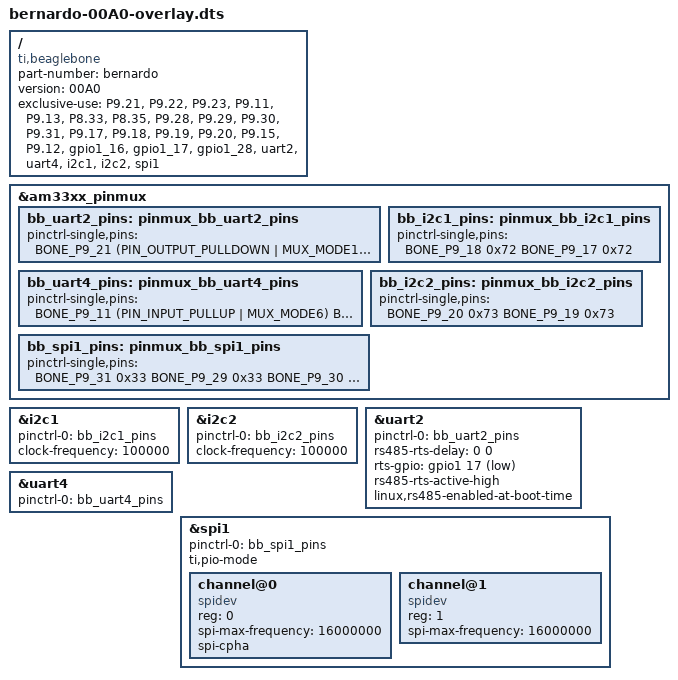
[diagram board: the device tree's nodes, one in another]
/* cape-bernardo.dts
* Written by Bert Outtier <outtierbert@gmail.com>
*
* TODO license
*/
/dts-v1/;
/plugin/;

#include <dt-bindings/board/am335x-bbw-bbb-base.h>
#include <dt-bindings/pinctrl/am33xx.h>

/ {
    compatible = "ti,beaglebone", "ti,beaglebone-black", "ti,beaglebone-green";

    /* identification */
    part-number = "bernardo";
    version = "00A0";

    /* state the resources this cape uses */
    exclusive-use =
    /* the pin header uses */

    /* rs485 */
    "P9.21", /* uart2_txd */
    "P9.22", /* uart2_rxd */
    "P9.23", /* uart2_dir = GPIO1_17 */

    /* rs232 */
    "P9.11", /* uart4_rxd */
    "P9.13", /* uart4_txd */
    "P8.33", /* uart4_rtsn */
    "P8.35", /* uart4_ctsn */

    /* spi */
    "P9.28", /* spi1_cs0 */
    "P9.29", /* spi1_d0 */
    "P9.30", /* spi1_d1 */
    "P9.31", /* spi1_sclk */
    // "P9.42", /* spi1_cs1 */

    /* i2c1 */
    "P9.17", /* i2c1_scl */
    "P9.18", /* i2c1_sda */

    /* i2c2 */
    "P9.19", /* i2c2_scl */
    "P9.20", /* i2c2_sda */
    "P9.15", /* i2c2_cfgwp = GPIO1_16 */
    "P9.12", /* i2c2_idwp = GPIO1_28 */

    /* Beaglelogic */
    //"P8.20", /* channel 13, shared with mmc1_cmd */
    //"P8.21", /* channel 14, shared with mmc1_clk */
    //"P8.27", /* channel 11 */
    //"P8.28", /* channel 12 */
    //"P8.29", /* channel 9 */
    //"P8.30", /* channel 10 */
    //"P8.39", /* channel 7 */
    //"P8.40", /* channel 8 */
    //"P8.41", /* channel 5 */
    //"P8.42", /* channel 6 */
    //"P8.43", /* channel 3 */
    //"P8.44", /* channel 4 */
    //"P8.45", /* channel 1 */
    //"P8.46", /* channel 2 */

    /* can1 */
    //"P9.24", /* dcan1_rx */
    //"P9.26", /* dcan1_tx */

    /* the hardware it uses */
    "gpio1_16",
    "gpio1_17",
    "gpio1_28",
    "uart2",
    "uart4",
    "i2c1",
    "i2c2",
    "spi1"
    //"dcan1"
    ;

    fragment@0 {
        target = <&am33xx_pinmux>;
        __overlay__ {
            bb_uart2_pins: pinmux_bb_uart2_pins {
                pinctrl-single,pins = <
                BONE_P9_21 (PIN_OUTPUT_PULLDOWN | MUX_MODE1) /* spi0_d0.uart2_txd */
                BONE_P9_22 (PIN_INPUT_PULLUP | MUX_MODE1) /* spi0_sclk.uart2_rxd */
                BONE_P9_23 (PIN_OUTPUT_PULLDOWN | MUX_MODE7) /* gpio */
                >;
            };

            bb_uart4_pins: pinmux_bb_uart4_pins {
                pinctrl-single,pins = <
                BONE_P9_11 (PIN_INPUT_PULLUP | MUX_MODE6) /* gpmc_wait0.uart4_rxd_mux2 */
                BONE_P9_13 (PIN_OUTPUT_PULLDOWN | MUX_MODE6) /* gpmc_wpn.uart4_txd_mux2 */
                BONE_P8_33 (PIN_OUTPUT | MUX_MODE6) /* rts */
                BONE_P8_35 (PIN_INPUT | MUX_MODE6) /* cts */
                >;
            };

            bb_i2c1_pins: pinmux_bb_i2c1_pins {
                pinctrl-single,pins = <
                BONE_P9_18 0x72	// spi0_d1.i2c1_sda, SLEWCTRL_SLOW | INPUT_PULLUP | MODE2
                BONE_P9_17 0x72	// spi0_cs0.i2c1_scl, SLEWCTRL_SLOW | INPUT_PULLUP | MODE2
                >;
            };

            bb_i2c2_pins: pinmux_bb_i2c2_pins {
                pinctrl-single,pins = <
                BONE_P9_20 0x73	/* i2c2_sda, SLEWCTRL_SLOW | INPUT_PULLUP | MODE3 */
                BONE_P9_19 0x73	/* i2c2_scl, SLEWCTRL_SLOW | INPUT_PULLUP | MODE3 */
                >;
            };

            bb_spi1_pins: pinmux_bb_spi1_pins {
                pinctrl-single,pins = <
                BONE_P9_31 0x33	/* mcasp0_aclkx.spi1_sclk, INPUT_PULLUP | MODE3 */
                BONE_P9_29 0x33	/* mcasp0_fsx.spi1_d0, INPUT_PULLUP | MODE3 */
                BONE_P9_30 0x13	/* mcasp0_axr0.spi1_d1, OUTPUT_PULLUP | MODE3 */
                BONE_P9_31 0x13	/* mcasp0_ahclkr.spi1_cs0, OUTPUT_PULLUP | MODE3 */
                // BONE_P9_42 0x12	/* eCAP0_in_PWM0_out.spi1_cs1 OUTPUT_PULLUP | MODE2 */
                >;
            };
        };
    };

    /* i2c1 */
    fragment@1 {
        target = <&i2c1>;	// i2c1 is numbered correctly
        __overlay__ {
            status = "okay";
            pinctrl-names = "default";
            pinctrl-0 = <&bb_i2c1_pins>;

            // configuration start
            clock-frequency = <100000>;

            #address-cells = <1>;
            #size-cells = <0>;

            // add any i2c devices on the bus here
            // commented out example of a touchscreen (taken from BB-BONE-LCD7-01-00A4)
            /*
            maxtouch@4a {
                compatible = "mXT224";
                reg = <0x4a>;
                interrupt-parent = <&gpio4>;
                interrupts = <19 0x0>;
                atmel,irq-gpio = <&gpio4 19 0>;
            };
            */
        };
    };

    /* i2c2 */
    fragment@2 {
        target = <&i2c2>;
        __overlay__ {
            status = "okay";
            pinctrl-names = "default";
            pinctrl-0 = <&bb_i2c2_pins>;

            /* this is the configuration part */
            clock-frequency = <100000>;

            #address-cells = <1>;
            #size-cells = <0>;

            /* add any i2c devices on the bus here */
            // commented out example of a touchscreen (taken from BB-BONE-LCD7-01-00A4) */
            /*
            maxtouch@4a {
                compatible = "mXT224";
            	reg = <0x4a>;
                interrupt-parent = <&gpio4>;
            	interrupts = <19 0x0>;
            	atmel,irq-gpio = <&gpio4 19 0>;
            };
            */
        };
    };

    /* rs485 - uart2 */
    fragment@3 {
        target = <&uart2>;
        __overlay__ {
            status = "okay";
            pinctrl-names = "default";
            pinctrl-0 = <&bb_uart2_pins>;
            rs485-rts-delay = <0 0>;

            rts-gpio = <&gpio1 17 1>; /*  GPIO_ACTIVE_HIGH>; */
            rs485-rts-active-high;
            linux,rs485-enabled-at-boot-time;
        };
    };

    /* rs232 - uart4 */
    fragment@4 {
        target = <&uart4>;
        __overlay__ {
            status = "okay";
            pinctrl-names = "default";
            pinctrl-0 = <&bb_uart4_pins>;
        };
    };

    /* spi */
    fragment@5 {
        target = <&spi1>;
        __overlay__ {
            #address-cells = <1>;
            #size-cells = <0>;

            status = "okay";
            pinctrl-names = "default";
            pinctrl-0 = <&bb_spi1_pins>;
            ti,pio-mode; /* disable dma when used as an overlay, dma gets stuck at 160 bits... */

            channel@0 {
                #address-cells = <1>;
                #size-cells = <0>;

                compatible = "spidev";

                reg = <0>;
                spi-max-frequency = <16000000>;
                spi-cpha;
            };

            channel@1 {
                #address-cells = <1>;
                #size-cells = <0>;

                compatible = "spidev";

                reg = <1>;
                spi-max-frequency = <16000000>;
            };
        };
    };
};
